# IOC register map
Vendor: Texas Instruments
Peripheral module from a debugger description file (folder UCD3138R064RSM).
Registers are 32-bit, read-write, no defined reset value unless marked. A register's access mark holds for its fields unless they carry their own. Offsets are as the file gives them; lines under a group give offsets from that group; [hi:lo] are bit positions; {n}, {i} and the like mark numbered series; 'fields as' and 'values as' point back to an identical list; <NAME> marks a mode.

## IOC — IO Controller
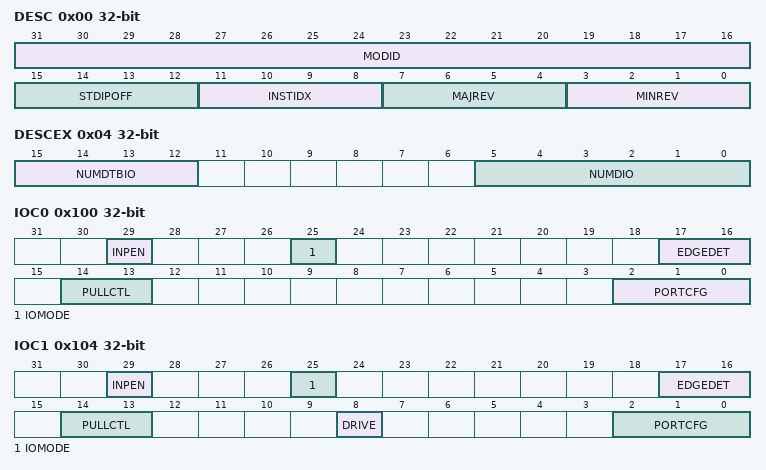
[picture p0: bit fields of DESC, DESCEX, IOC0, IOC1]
0x00 DESC access not given — This register identifies the peripheral and its exact version.
  [31:16] MODID — Module identification contains a unique peripheral identification number.
    0xFFFF=MAXIMUM (Highest possible value); 0=MINIMUM (Smallest value)
  [15:12] STDIPOFF — Standard IP registers offset. Value 0 indicates Standard IP registers are not present. Any other value between 1 to 15 indicates standard IP registers start from address offset 64 * STDIPOFF from base address.
    15=MAXIMUM (Highest possible value); 0=MINIMUM (Smallest value)
  [11:8] INSTIDX — Instance Index within the device. This will be a parameter to the RTL for modules that can have multiple instances.
    values as STDIPOFF
  [7:4] MAJREV — Major rev of the IP
    values as STDIPOFF
  [3:0] MINREV — Minor rev of the IP
    values as STDIPOFF
0x04 DESCEX access not given — This register describes the configuration of IOC.
  [15:12] NUMDTBIO — Number of DTB IOs supported. Total DTB IOs supported is NUMDTBIO value +1.
    values as DESC.STDIPOFF
  [5:0] NUMDIO — Number of DIOs supported. Total DIOs supported is NUMDIO value +1.
    63=MAXIMUM (Highest possible value); 0=MINIMUM (Smallest value)
0x64 DTB — Digital Test Bus. This register is used to bring out some internal signals of the peripheral on digital test bus (DTB).
  [2:0] SEL — This bit field is used to select DTB mux digital output signals.
    0=DISABLE (DTB output from peripheral is 0x0); {v}=GRP{v} (Selects test group {v}) (v=1..7)
0x68 FAULTDIR — Fault direction register
  [2:0] FLT
0x6C FAULTIN ro — Fault input
  [2:0] FLT
0x70 FAULTOUT — Fault output register
  [2:0] FLT
0x100 IOC0 — Configuration
  [29] INPEN — Input enable
    0=DISABLE (Input disabled); 1=ENABLE (Input enabled)
  [25] IOMODE
    0=NORMAL (Normal IO); 1=OPEND (Open Drain, normal IO)
  [17:16] EDGEDET — Edge detect configuration
    0=EDGE_DIS (No edge detection); 1=EDGE_NEG (Negative edge detection); 2=EDGE_POS (Positive edge detection); 3=EDGE_BOTH (Positive and negative edge detection)
  [14:13] PULLCTL — Pull control.
    0=PULL_DOWN (Pull down enabled); 1=PULL_UP (Pull up enabled); 2=PULL_DIS (No pull); 3=PULL_DIS1 (No pull)
  [2:0] PORTCFG — Port configuration.
    0=BASE (Base function); {v}=PFUNC{v} (Digital peripheral function-{v}) (v=1..5); 6=GPIO (GPIO function); 7=DTB (Digital Test Bus function)
0x104 IOC1 — Configuration
  [29] INPEN — Input enable
    0=DISABLE (Input disabled); 1=ENABLE (Input enabled)
  [25] IOMODE
    0=NORMAL (Normal IO); 1=OPEND (Open Drain, normal IO)
  [17:16] EDGEDET — Edge detect configuration
    values as IOC0.EDGEDET
  [14:13] PULLCTL — Pull control.
    values as IOC0.PULLCTL
  [8] DRIVE — Drive for PMBUS pads.
    0=LOW_DRIVE (Drive of 4mA); 1=HIGH_DRIVE (Drive of 20mA(Pull down only))
  [2:0] PORTCFG — Port configuration.
    values as IOC0.PORTCFG
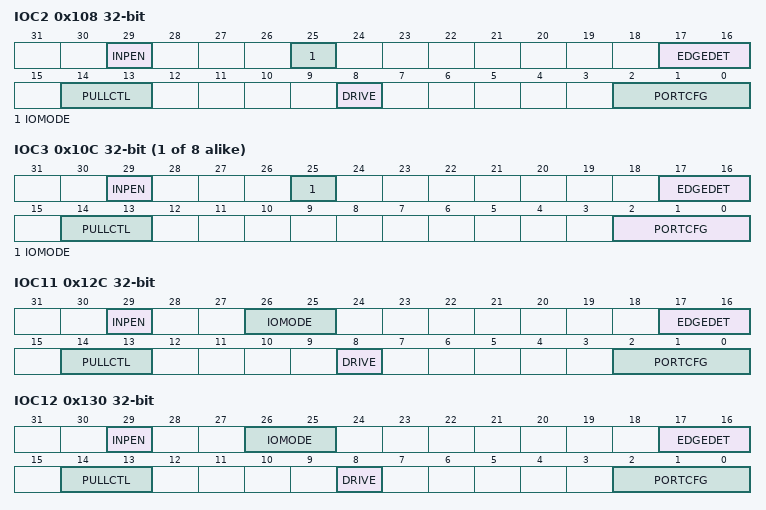
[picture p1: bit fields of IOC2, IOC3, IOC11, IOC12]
0x108 IOC2 — Configuration
  fields as IOC1
{0x100+4i} IOC{i} (i=3..10) — Configuration
  fields as IOC0
0x12C IOC11 — Configuration
  [29] INPEN — Input enable
    0=DISABLE (Input disabled); 1=ENABLE (Input enabled)
  [26:25] IOMODE
    0=NORMAL (Normal IO); 1=OPEND (Open Drain, normal IO); 2=INVERTED (Inverted IO); 3=OPEND_INV (Open Drain, inverted IO)
  [17:16] EDGEDET — Edge detect configuration
    values as IOC0.EDGEDET
  [14:13] PULLCTL — Pull control.
    values as IOC0.PULLCTL
  [8] DRIVE — Drive for PMBUS pads.
    values as IOC1.DRIVE
  [2:0] PORTCFG — Port configuration.
    values as IOC0.PORTCFG
0x130 IOC12 — Configuration
  [29] INPEN — Input enable
    0=DISABLE (Input disabled); 1=ENABLE (Input enabled)
  [26:25] IOMODE — IO Mode. Setting this to value 0x6 or 0x7 will default to normal IO behavior.
    values as IOC11.IOMODE
  [17:16] EDGEDET — Edge detect configuration
    values as IOC0.EDGEDET
  [14:13] PULLCTL — Pull control.
    values as IOC0.PULLCTL
  [8] DRIVE — Drive for PMBUS pads.
    values as IOC1.DRIVE
  [2:0] PORTCFG — Port configuration.
    values as IOC0.PORTCFG
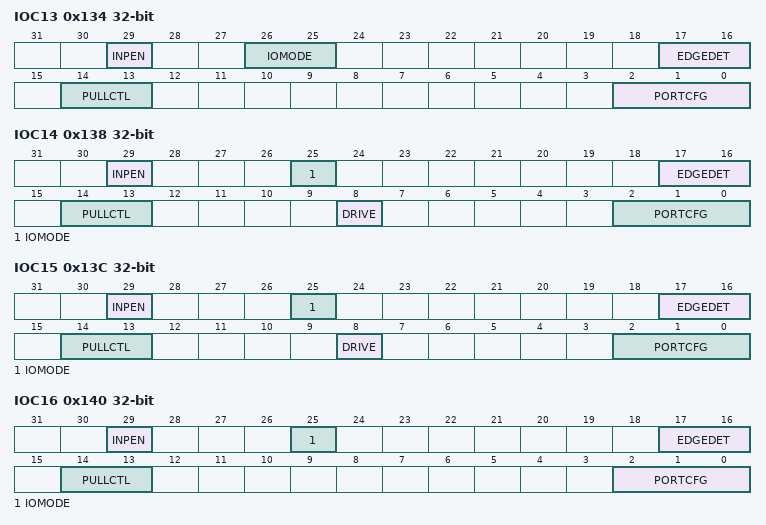
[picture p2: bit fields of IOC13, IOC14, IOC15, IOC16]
0x134 IOC13 — Configuration
  [29] INPEN — Input enable
    0=DISABLE (Input disabled); 1=ENABLE (Input enabled)
  [26:25] IOMODE — IO Mode. Setting this to value 0x6 or 0x7 will default to normal IO behavior.
    values as IOC11.IOMODE
  [17:16] EDGEDET — Edge detect configuration
    values as IOC0.EDGEDET
  [14:13] PULLCTL — Pull control.
    values as IOC0.PULLCTL
  [2:0] PORTCFG — Port configuration.
    values as IOC0.PORTCFG
0x138 IOC14 — Configuration
  fields as IOC1
0x13C IOC15 — Configuration
  fields as IOC1
0x140 IOC16 — Configuration
  fields as IOC0
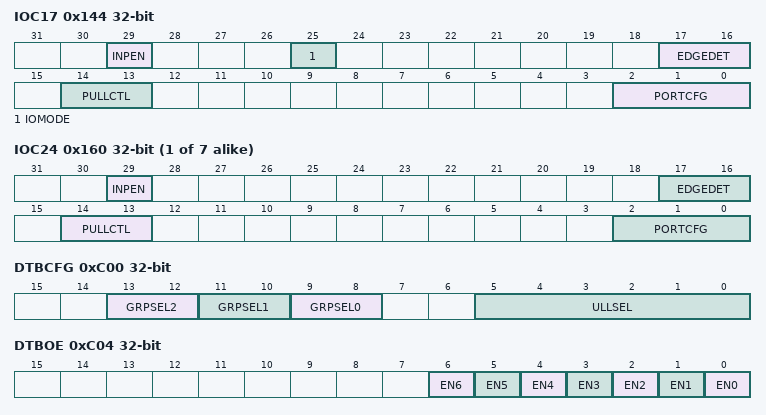
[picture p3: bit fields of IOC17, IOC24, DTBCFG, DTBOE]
0x144 IOC17 — Configuration
  fields as IOC0
{0x100+4i} IOC{i} (i=24..30) — Configuration
  [29] INPEN — Input enable
    0=DISABLE (Input disabled); 1=ENABLE (Input enabled)
  [17:16] EDGEDET — Edge detect configuration
    values as IOC0.EDGEDET
  [14:13] PULLCTL — Pull control.
    values as IOC0.PULLCTL
  [2:0] PORTCFG — Port configuration.
    values as IOC0.PORTCFG
0xC00 DTBCFG access not given — DTB configuration
  [13:12] GRPSEL2 — DTB group select1 for DTB5, DTB6 and DTB7 pads
  [11:10] GRPSEL1 — DTB group select1 for DTB3 and DTB4 pads
  [9:8] GRPSEL0 — DTB group select0 for DTB1 and DTB2 pads
  [5:0] ULLSEL rw — ULL DTB Mux selection
    0=MINIMUM (Minimum value); 31=MAXIMUM (Maximum value)
0xC04 DTBOE — DTB output enable
  [all] fields
    0=DISABLE (DTB output disabled); 1=ENABLE (DTB output enabled)
  [n] EN{n} (n=0..6) — Enables DTB output {n}
0xC0C TEST
  [0] SEL — This is used to drive SWDIO output data and output enable from debug sub-system onto TBD (TDO) pad.
    0=LOW (Output data and output enable managed by IOC); 1=HIGH (Output data and output enable driven based on debug sub-system inputs)
0xC10 DTBSTAT — DTB status register. This register captures the value of DTBL3 mux layer output.
  [7:0] VAL — This bit field captures the final 16-bit value of DTB signals provided from IOC to DTB device pins.
